# VIP1_Slice0_csc register map
Vendor: Texas Instruments
Peripheral module from a debugger description file (folder am571x).
Registers are 32-bit, read-write, reset 0x0 unless marked. A register's access mark holds for its fields unless they carry their own. Offsets are as the file gives them; lines under a group give offsets from that group; [hi:lo] are bit positions; {n}, {i} and the like mark numbered series; 'fields as' and 'values as' point back to an identical list; <NAME> marks a mode.

## VIP1_Slice0_csc
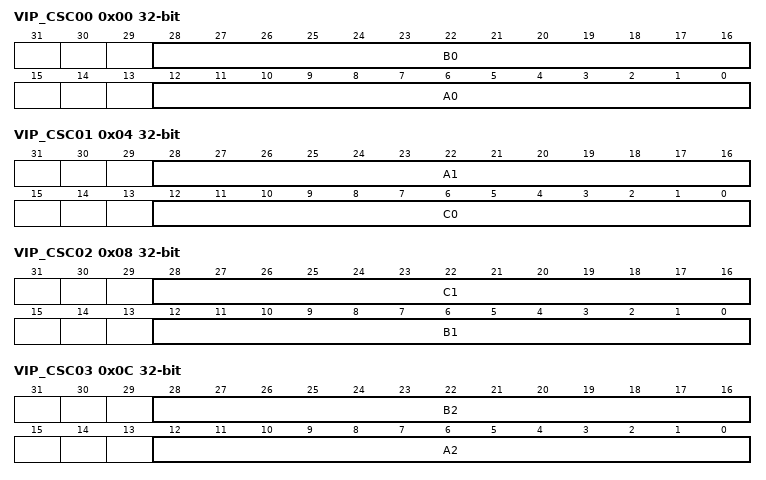
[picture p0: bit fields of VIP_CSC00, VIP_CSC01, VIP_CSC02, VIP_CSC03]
0x00 VIP_CSC00
  [28:16] B0 — Coefficients of color space converter. This coefficient is a real number in the range of 4. The MSB is sign bit. (Same format conversion as A0)
  [12:0] A0 — Coefficients of color space converter. This coefficient is a real number in the range of 4. The MSB is sign bit. Rules for converting a real number coefficient to a 12-bit hex number for this register: - If the real number is positive, then simply multiply it by 1024, and convert the integer part to hex format. For example, 0.673 X 1024 = 689.152, then 0x2B1 should fill in to this register - If the real number is negative, then multiply it by 1024, and convert it to 2's compliment format in 12-bit. For example, if a coefficient is -1.893, by *1024 to this number, it becomes -1938. The 2'S compliment format of -1938 is 0x186E (in 13-bit width). Then 0x186E should be the number assigned to this register.
0x04 VIP_CSC01
  [28:16] A1 — Coefficients of color space converter. This coefficient is a real number in the range of 4. The MSB is sign bit. (Same format conversion as A0)
  [12:0] C0 — Coefficients of color space converter. This coefficient is a real number in the range of 4. The MSB is sign bit. (Same format conversion as A0)
0x08 VIP_CSC02
  [28:16] C1 — Coefficients of color space converter. This coefficient is a real number in the range of 4. The MSB is sign bit. (Same format conversion as A0)
  [12:0] B1 — Coefficients of color space converter. This coefficient is a real number in the range of 4. The MSB is sign bit. (Same format conversion as A0)
0x0C VIP_CSC03
  [28:16] B2 — Coefficients of color space converter. This coefficient is a real number in the range of 4. The MSB is sign bit. (Same format conversion as A0)
  [12:0] A2 — Coefficients of color space converter. This coefficient is a real number in the range of 4. The MSB is sign bit. (Same format conversion as A0)
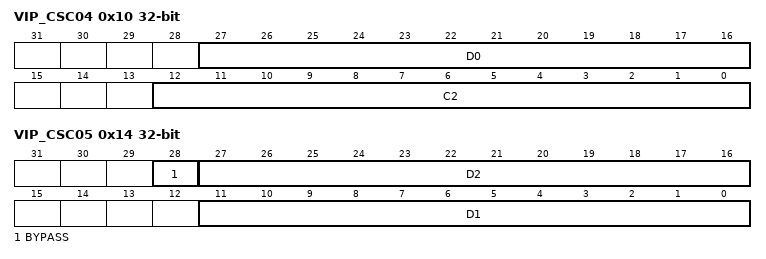
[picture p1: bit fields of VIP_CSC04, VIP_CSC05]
0x10 VIP_CSC04
  [27:16] D0 — Coefficients of color space converter. This coefficient is an integer number in the range of 2048. It is in 12-bit wide 2's compliment format. The MSB is sign bit. For example, if this coefficient is 749, then 0x2ED (hex format) should be assigned to this register. Another example, if this coefficient is -1021, then 0xC03 should be assigned to this register.
  [12:0] C2 — Coefficients of color space converter. This coefficient is a real number in the range of 4. The MSB is sign bit. (Same format conversion as A0)
0x14 VIP_CSC05
  [28] BYPASS — Full CSC bypass mode
  [27:16] D2 — Coefficients of color space converter. This coefficient is an integer number in the range of 2048. It is in 12-bit wide 2's compliment format. The MSB is sign bit. (Same format conversion as D0)
  [11:0] D1 — Coefficients of color space converter. This coefficient is an integer number in the range of 2048. It is in 12-bit wide 2's compliment format. The MSB is sign bit. (Same format conversion as D0)
